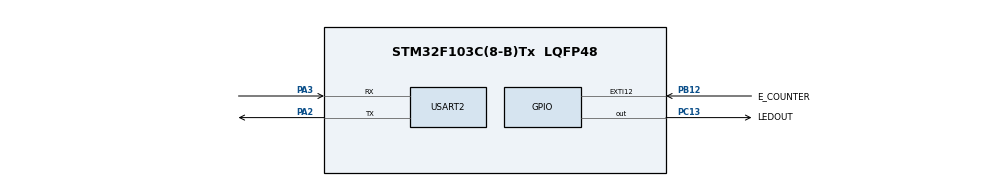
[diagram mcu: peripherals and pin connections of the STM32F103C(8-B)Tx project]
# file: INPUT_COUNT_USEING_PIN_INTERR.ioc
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Mcu.Family=STM32F1
Mcu.Name=STM32F103C(8-B)Tx
Mcu.Package=LQFP48
NVIC.EXTI15_10_IRQn=true\:0\:0\:false\:false\:true\:true\:true\:true
NVIC.PriorityGroup=NVIC_PRIORITYGROUP_4
PA13.Mode=Serial_Wire
PA13.Signal=SYS_JTMS-SWDIO
PA14.Mode=Serial_Wire
PA14.Signal=SYS_JTCK-SWCLK
PA2.Mode=Asynchronous
PA2.Signal=USART2_TX
PA3.Mode=Asynchronous
PA3.Signal=USART2_RX
PB12.GPIO_Label=E_COUNTER
PB12.GPIO_ModeDefaultEXTI=GPIO_MODE_IT_FALLING
PB12.Signal=GPXTI12
PC13-TAMPER-RTC.GPIO_Label=LEDOUT
PC13-TAMPER-RTC.Signal=GPIO_Output
ProjectManager.HeapSize=0x200
ProjectManager.StackSize=0x400
ProjectManager.TargetToolchain=MDK-ARM V5.27
RCC.APB1Freq_Value=8000000
RCC.APB2Freq_Value=8000000
USART2.VirtualMode=VM_ASYNC
board=custom

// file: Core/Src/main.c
/* USER CODE BEGIN Header */
/**
  ******************************************************************************
  * @file           : main.c
  * @brief          : Main program body
  ******************************************************************************
  * @attention
  *
  * Copyright (c) 2026 STMicroelectronics.
  * All rights reserved.
  *
  * This software is licensed under terms that can be found in the LICENSE file
  * in the root directory of this software component.
  * If no LICENSE file comes with this software, it is provided AS-IS.
  *
  ******************************************************************************
  */
/* USER CODE END Header */
#include "main.h"
#include "string.h"
#include <stdio.h>

UART_HandleTypeDef huart2;

void SystemClock_Config(void);
static void MX_GPIO_Init(void);
static void MX_USART2_UART_Init(void);

/* USER CODE BEGIN 0 */
volatile uint32_t counter = 0,last_count = 0;
char buf[30];

/* USER CODE END 0 */

int main(void)
{

  /* MCU Configuration--------------------------------------------------------*/

  /* Reset of all peripherals, Initializes the Flash interface and the Systick. */
  HAL_Init();

  /* Configure the system clock */
  SystemClock_Config();

  /* Initialize all configured peripherals */
  MX_GPIO_Init();
  MX_USART2_UART_Init();

  /* Infinite loop */
  while (1)
  {
		if(last_count != counter)
		{
			last_count = counter;
			sprintf(buf, "Count: %lu\r\n", (unsigned long) last_count);
			HAL_UART_Transmit(&huart2,(uint8_t*)buf,strlen(buf),100);
		}

  }
}

void SystemClock_Config(void)
{
  RCC_OscInitTypeDef RCC_OscInitStruct = {0};
  RCC_ClkInitTypeDef RCC_ClkInitStruct = {0};

  /** Initializes the RCC Oscillators according to the specified parameters
  * in the RCC_OscInitTypeDef structure.
  */
  RCC_OscInitStruct.OscillatorType = RCC_OSCILLATORTYPE_HSI;
  RCC_OscInitStruct.HSIState = RCC_HSI_ON;
  RCC_OscInitStruct.HSICalibrationValue = RCC_HSICALIBRATION_DEFAULT;
  RCC_OscInitStruct.PLL.PLLState = RCC_PLL_NONE;
  if (HAL_RCC_OscConfig(&RCC_OscInitStruct) != HAL_OK)
  {
    Error_Handler();
  }

  /** Initializes the CPU, AHB and APB buses clocks
  */
  RCC_ClkInitStruct.ClockType = RCC_CLOCKTYPE_HCLK|RCC_CLOCKTYPE_SYSCLK
                              |RCC_CLOCKTYPE_PCLK1|RCC_CLOCKTYPE_PCLK2;
  RCC_ClkInitStruct.SYSCLKSource = RCC_SYSCLKSOURCE_HSI;
  RCC_ClkInitStruct.AHBCLKDivider = RCC_SYSCLK_DIV1;
  RCC_ClkInitStruct.APB1CLKDivider = RCC_HCLK_DIV1;
  RCC_ClkInitStruct.APB2CLKDivider = RCC_HCLK_DIV1;

  if (HAL_RCC_ClockConfig(&RCC_ClkInitStruct, FLASH_LATENCY_0) != HAL_OK)
  {
    Error_Handler();
  }
}

static void MX_USART2_UART_Init(void)
{

  huart2.Instance = USART2;
  huart2.Init.BaudRate = 115200;
  huart2.Init.WordLength = UART_WORDLENGTH_8B;
  huart2.Init.StopBits = UART_STOPBITS_1;
  huart2.Init.Parity = UART_PARITY_NONE;
  huart2.Init.Mode = UART_MODE_TX_RX;
  huart2.Init.HwFlowCtl = UART_HWCONTROL_NONE;
  huart2.Init.OverSampling = UART_OVERSAMPLING_16;
  if (HAL_UART_Init(&huart2) != HAL_OK)
  {
    Error_Handler();
  }

}

static void MX_GPIO_Init(void)
{
  GPIO_InitTypeDef GPIO_InitStruct = {0};

  /* GPIO Ports Clock Enable */
  __HAL_RCC_GPIOC_CLK_ENABLE();
  __HAL_RCC_GPIOA_CLK_ENABLE();
  __HAL_RCC_GPIOB_CLK_ENABLE();

  /*Configure GPIO pin Output Level */
  HAL_GPIO_WritePin(LEDOUT_GPIO_Port, LEDOUT_Pin, GPIO_PIN_RESET);

  /*Configure GPIO pin : LEDOUT_Pin */
  GPIO_InitStruct.Pin = LEDOUT_Pin;
  GPIO_InitStruct.Mode = GPIO_MODE_OUTPUT_PP;
  GPIO_InitStruct.Pull = GPIO_NOPULL;
  GPIO_InitStruct.Speed = GPIO_SPEED_FREQ_LOW;
  HAL_GPIO_Init(LEDOUT_GPIO_Port, &GPIO_InitStruct);

  /*Configure GPIO pin : E_COUNTER_Pin */
  GPIO_InitStruct.Pin = E_COUNTER_Pin;
  GPIO_InitStruct.Mode = GPIO_MODE_IT_RISING;
  GPIO_InitStruct.Pull = GPIO_NOPULL;
  HAL_GPIO_Init(E_COUNTER_GPIO_Port, &GPIO_InitStruct);

  /* EXTI interrupt init*/
  HAL_NVIC_SetPriority(EXTI15_10_IRQn, 0, 0);
  HAL_NVIC_EnableIRQ(EXTI15_10_IRQn);

}

/* USER CODE BEGIN 4 */
void HAL_GPIO_EXTI_Callback(uint16_t GPIO_Pin)
{
  if(GPIO_Pin == E_COUNTER_Pin)
  {
   counter++;
		HAL_GPIO_TogglePin(GPIOC, GPIO_PIN_13);
  }
}

/* USER CODE END 4 */

void Error_Handler(void)
{
  __disable_irq();
  while (1)
  {
  }
}
